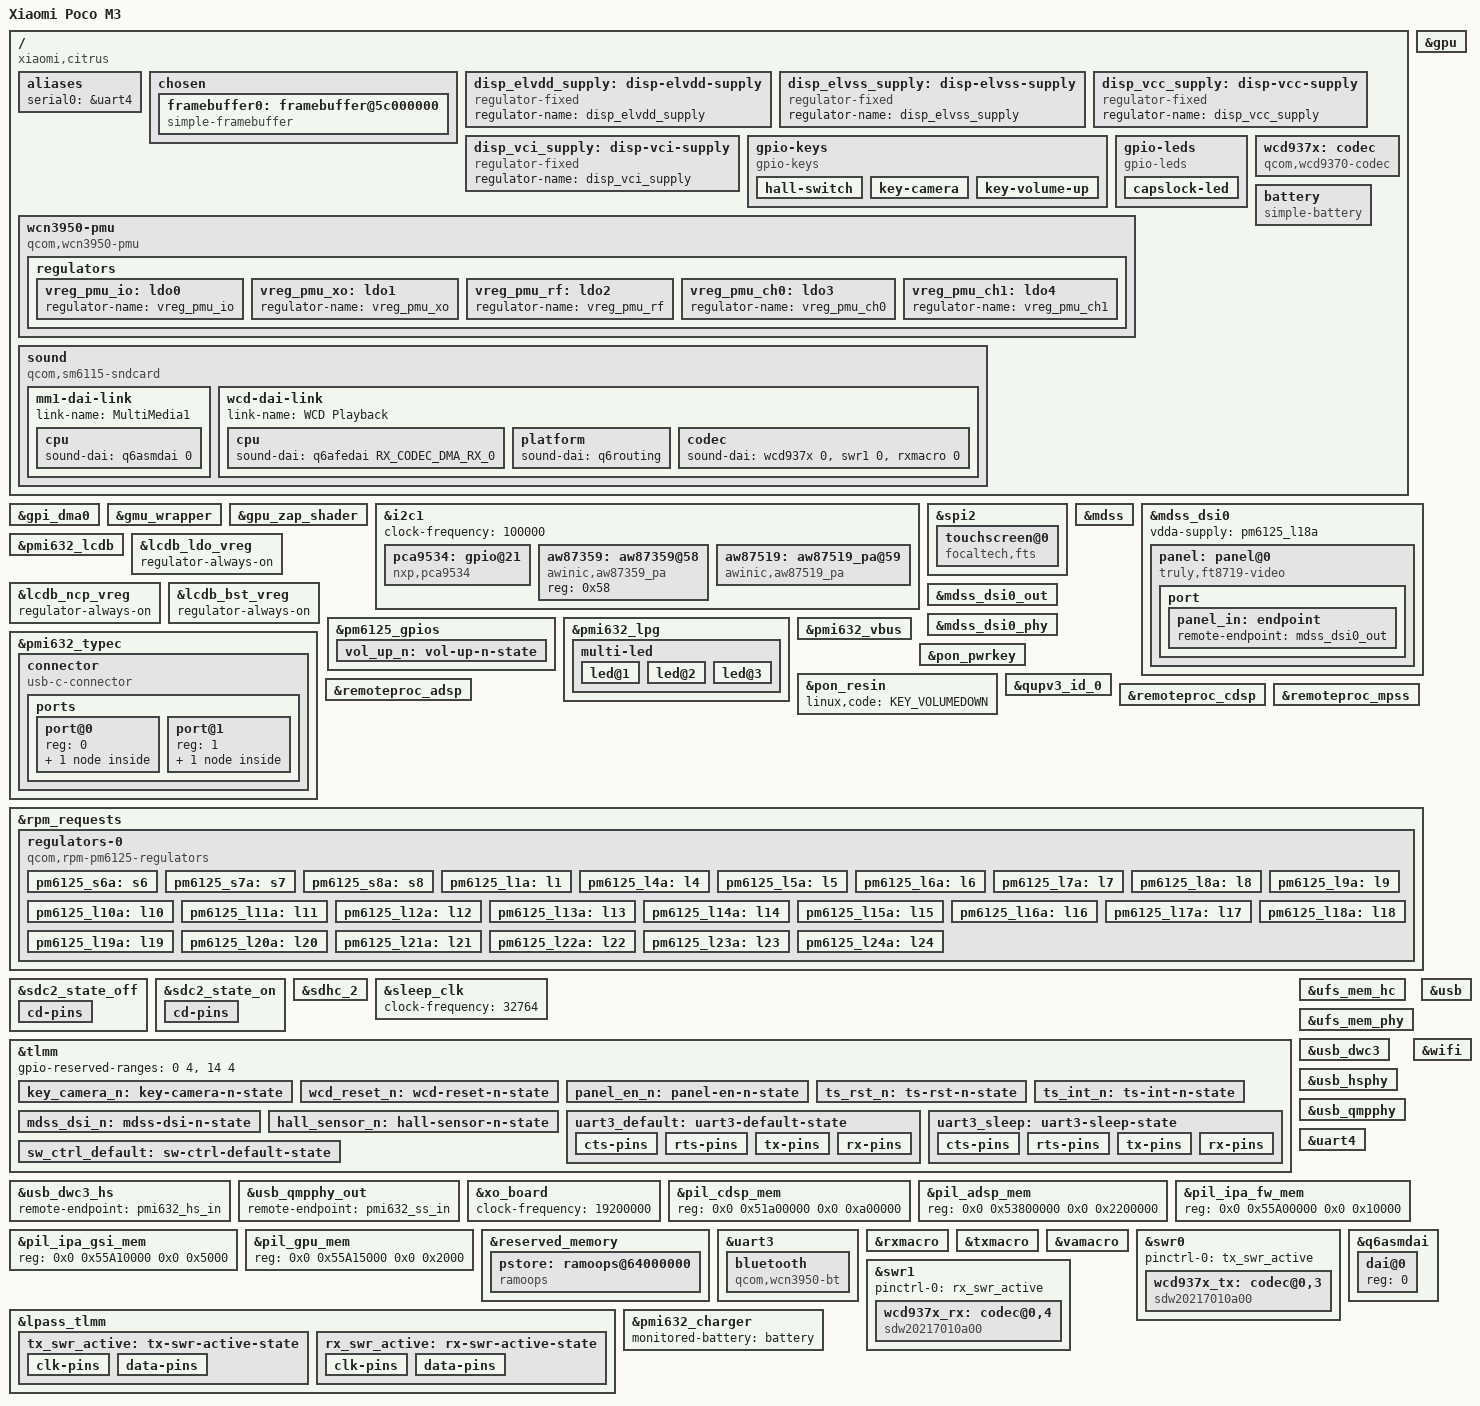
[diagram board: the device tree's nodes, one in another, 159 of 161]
// SPDX-License-Identifier: (GPL-2.0+ OR BSD-3-Clause)
/*
 * Copyright (c) 2023 - 2024, Dang Huynh <danct12@riseup.net>
 */

/dts-v1/;

#include "sm6115.dtsi"
#include "pm6125.dtsi"
#include "pmi632.dtsi"
#include <dt-bindings/arm/qcom,ids.h>
#include <dt-bindings/leds/common.h>
#include <dt-bindings/usb/pd.h>
#include <dt-bindings/interconnect/qcom,sm6115.h>

/ {
	model = "Xiaomi Poco M3";
	compatible = "xiaomi,citrus", "qcom,sm6115";
	chassis-type = "handset";

	qcom,msm-id = <0x1a1 0x10000 0x1bc 0x10000>;
	qcom,board-id = <0x00 0x303>;

	aliases {
		serial0 = &uart4;
	};

	chosen {
		#address-cells = <2>;
		#size-cells = <2>;
		ranges;

		framebuffer0: framebuffer@5c000000 {
			compatible = "simple-framebuffer";
			reg = <0x0 0x5c000000 0x0 (1080 * 2160 * 4)>;
			width = <1080>;
			height = <2160>;
			stride = <(1080 * 4)>;
			format = "a8r8g8b8";
			clocks = <&gcc GCC_DISP_HF_AXI_CLK>;
		};
	};

	disp_elvdd_supply: disp-elvdd-supply {
		compatible = "regulator-fixed";
		regulator-name = "disp_elvdd_supply";
	};

	disp_elvss_supply: disp-elvss-supply {
		compatible = "regulator-fixed";
		regulator-name = "disp_elvss_supply";
	};

	disp_vcc_supply: disp-vcc-supply {
		compatible = "regulator-fixed";
		regulator-name = "disp_vcc_supply";
	};

	disp_vci_supply: disp-vci-supply {
		compatible = "regulator-fixed";
		regulator-name = "disp_vci_supply";
	};

	gpio-keys {
		compatible = "gpio-keys";

		pinctrl-0 = <&hall_sensor_n>, <&key_camera_n>, <&vol_up_n>;
		pinctrl-names = "default";

		hall-switch {
			label = "Hall Switch";
			linux,input-type = <EV_SW>;
			linux,code = <SW_LID>;
			gpios = <&tlmm 96 GPIO_ACTIVE_HIGH>;
			debounce-interval = <90>;
			wakeup-source;
		};

		key-camera {
			label = "Camera Button";
			linux,code = <KEY_CAMERA>;
			gpios = <&tlmm 18 GPIO_ACTIVE_LOW>;
			debounce-interval = <15>;
		};

		key-volume-up {
			label = "Volume Up";
			linux,code = <KEY_VOLUMEUP>;
			gpios = <&pm6125_gpios 5 GPIO_ACTIVE_LOW>;
			debounce-interval = <15>;
			linux,can-disable;
			wakeup-source;
		};
	};

	gpio-leds {
		compatible = "gpio-leds";

		capslock-led {
			label = "green:capslock";
			function = LED_FUNCTION_CAPSLOCK;
			color = <LED_COLOR_ID_GREEN>;
			gpios = <&pca9534 1 GPIO_ACTIVE_HIGH>;
			linux,default-trigger = "kbd-capslock";
			default-state = "off";
		};
	};

};

&gpi_dma0 {
	status = "okay";
};

&gpu {
	status = "okay";
};

&gmu_wrapper {
	interconnects = <&bimc MASTER_GRAPHICS_3D 0 &bimc SLAVE_EBI_CH0 0>;
	interconnect-names = "gfx-mem";
};

&gpu_zap_shader {
	firmware-name = "qcom/sm6115/xiaomi-citrus/a610_zap.mbn";
};

&i2c1 {
	clock-frequency = <100000>;

	status = "okay";

	pca9534: gpio@21 {
		compatible = "nxp,pca9534";
		reg = <0x21>;
		gpio-controller;
		#gpio-cells = <2>;
	};

	aw87359: aw87359@58 {
		compatible = "awinic,aw87359_pa";
		reg = <0x58>;
	};

	aw87519: aw87519_pa@59 {
		compatible = "awinic,aw87519_pa";
		reg = <0x59>;
		reset-gpios = <&tlmm 98 GPIO_ACTIVE_HIGH>;
	};
};

&spi2 {
	status = "okay";


	touchscreen@0 {
		compatible = "focaltech,fts";
		reg = <0>;
		spi-max-frequency = <6000000>;

		focaltech,reset-gpios = <&tlmm 103 GPIO_ACTIVE_LOW>;
		focaltech,irq-gpios = <&tlmm 93 GPIO_ACTIVE_HIGH>;

		focaltech,max-touch-number = <10>;
		focaltech,display-coords = <0 0 1080 2340>;
	};
};

&mdss {
	status = "okay";
};

&mdss_dsi0 {
	vdda-supply = <&pm6125_l18a>;
	status = "okay";

	panel: panel@0 {
		compatible = "truly,ft8719-video";
		reg = <0>;

		reset-gpios = <&tlmm 82 GPIO_ACTIVE_LOW>;

		vddio-supply = <&pm6125_l9a>;

		pinctrl-0 = <&mdss_dsi_n &panel_en_n>;
		pinctrl-names = "default";

		port {
			panel_in: endpoint {
				remote-endpoint = <&mdss_dsi0_out>;
			};
		};
	};
};

&pmi632_lcdb {
	status = "okay";
};

&lcdb_ldo_vreg {
	regulator-always-on;
};

&lcdb_ncp_vreg {
	regulator-always-on;
};

&lcdb_bst_vreg {
	regulator-always-on;
};

&mdss_dsi0_out {
	data-lanes = <0 1 2 3>;
	remote-endpoint = <&panel_in>;
};

&mdss_dsi0_phy {
	status = "okay";
};

&pm6125_gpios {
	vol_up_n: vol-up-n-state {
		pins = "gpio5";
		function = "normal";
		power-source = <0>;
		bias-pull-up;
		input-enable;
	};
};

&pmi632_lpg {
	status = "okay";

	multi-led {
		color = <LED_COLOR_ID_RGB>;
		function = LED_FUNCTION_STATUS;

		#address-cells = <1>;
		#size-cells = <0>;

		led@1 {
			reg = <1>;
			color = <LED_COLOR_ID_RED>;
		};

		led@2 {
			reg = <2>;
			color = <LED_COLOR_ID_GREEN>;
		};

		led@3 {
			reg = <3>;
			color = <LED_COLOR_ID_BLUE>;
		};
	};
};

&pmi632_typec {
	status = "okay";

	connector {
		compatible = "usb-c-connector";

		power-role = "dual";
		data-role = "dual";
		self-powered;

		typec-power-opmode = "default";
		pd-disable;

		vbus-supply = <&pmi632_vbus>;

		ports {
			#address-cells = <1>;
			#size-cells = <0>;

			port@0 {
				reg = <0>;
				pmi632_hs_in: endpoint {
					remote-endpoint = <&usb_dwc3_hs>;
				};
			};

			port@1 {
				reg = <1>;
				pmi632_ss_in: endpoint {
					remote-endpoint = <&usb_qmpphy_out>;
				};
			};
		};
	};
};

&pmi632_vbus {
	regulator-min-microamp = <500000>;
	regulator-max-microamp = <1000000>;
	status = "okay";
};

&pon_pwrkey {
	status = "okay";
};

&pon_resin {
	linux,code = <KEY_VOLUMEDOWN>;
	status = "okay";
};

&qupv3_id_0 {
	status = "okay";
};

&remoteproc_adsp {
	firmware-name = "qcom/sm6115/xiaomi-citrus/adsp.mdt";
	status = "okay";
};

&remoteproc_cdsp {
	firmware-name = "qcom/sm6115/xiaomi-citrus/cdsp.mdt";
	status = "okay";
};

&remoteproc_mpss {
	firmware-name = "qcom/sm6115/xiaomi-citrus/modem.mdt";
	status = "okay";
};

&rpm_requests {
	regulators-0 {
		compatible = "qcom,rpm-pm6125-regulators";

		pm6125_s6a: s6 {
			regulator-min-microvolt = <304000>;
			regulator-max-microvolt = <1456000>;
		};

		pm6125_s7a: s7 {
			regulator-min-microvolt = <1280000>;
			regulator-max-microvolt = <2040000>;
		};

		pm6125_s8a: s8 {
			regulator-min-microvolt = <1064000>;
			regulator-max-microvolt = <1304000>;
		};

		pm6125_l1a: l1 {
			regulator-min-microvolt = <952000>;
			regulator-max-microvolt = <1152000>;
		};

		pm6125_l4a: l4 {
			regulator-min-microvolt = <488000>;
			regulator-max-microvolt = <1000000>;
		};

		pm6125_l5a: l5 {
			regulator-min-microvolt = <1648000>;
			regulator-max-microvolt = <3056000>;
			regulator-allow-set-load;
		};

		pm6125_l6a: l6 {
			regulator-min-microvolt = <576000>;
			regulator-max-microvolt = <656000>;
		};

		pm6125_l7a: l7 {
			regulator-min-microvolt = <1200000>;
			regulator-max-microvolt = <1304000>;
		};

		pm6125_l8a: l8 {
			regulator-min-microvolt = <400000>;
			regulator-max-microvolt = <728000>;
		};

		pm6125_l9a: l9 {
			regulator-min-microvolt = <1800000>;
			regulator-max-microvolt = <2000000>;
		};

		pm6125_l10a: l10 {
			regulator-min-microvolt = <1704000>;
			regulator-max-microvolt = <1904000>;
		};

		pm6125_l11a: l11 {
			regulator-min-microvolt = <1704000>;
			regulator-max-microvolt = <1952000>;
			regulator-allow-set-load;
		};

		pm6125_l12a: l12 {
			regulator-min-microvolt = <1624000>;
			regulator-max-microvolt = <1984000>;
		};

		pm6125_l13a: l13 {
			regulator-min-microvolt = <1504000>;
			regulator-max-microvolt = <1952000>;
		};

		pm6125_l14a: l14 {
			regulator-min-microvolt = <1704000>;
			regulator-max-microvolt = <1904000>;
		};

		pm6125_l15a: l15 {
			regulator-min-microvolt = <2920000>;
			regulator-max-microvolt = <3232000>;
		};

		pm6125_l16a: l16 {
			regulator-min-microvolt = <1704000>;
			regulator-max-microvolt = <1904000>;
		};

		pm6125_l17a: l17 {
			regulator-min-microvolt = <1152000>;
			regulator-max-microvolt = <1384000>;
		};

		pm6125_l18a: l18 {
			regulator-min-microvolt = <1104000>;
			regulator-max-microvolt = <1312000>;
		};

		pm6125_l19a: l19 {
			regulator-min-microvolt = <1624000>;
			regulator-max-microvolt = <3304000>;
		};

		pm6125_l20a: l20 {
			regulator-min-microvolt = <1624000>;
			regulator-max-microvolt = <3304000>;
		};

		pm6125_l21a: l21 {
			regulator-min-microvolt = <2400000>;
			regulator-max-microvolt = <3600000>;
		};

		pm6125_l22a: l22 {
			regulator-min-microvolt = <2952000>;
			regulator-max-microvolt = <3304000>;
		};

		pm6125_l23a: l23 {
			regulator-min-microvolt = <3200000>;
			regulator-max-microvolt = <3400000>;
		};

		pm6125_l24a: l24 {
			regulator-min-microvolt = <2704000>;
			regulator-max-microvolt = <3600000>;
			regulator-allow-set-load;
		};
	};
};

&sdc2_state_off {
	cd-pins {
		pins = "gpio88";
		function = "gpio";
		drive-strength = <2>;
		bias-disable;
	};
};

&sdc2_state_on {
	cd-pins {
		pins = "gpio88";
		function = "gpio";
		drive-strength = <2>;
		bias-pull-up;
	};
};

&sdhc_2 {
	pinctrl-0 = <&sdc2_state_on>;
	pinctrl-1 = <&sdc2_state_off>;
	pinctrl-names = "default", "sleep";

	cd-gpios = <&tlmm 88 GPIO_ACTIVE_HIGH>;

	vmmc-supply = <&pm6125_l22a>;
	vqmmc-supply = <&pm6125_l5a>;

	status = "okay";
};

&sleep_clk {
	clock-frequency = <32764>;
};

&tlmm {
	gpio-reserved-ranges = <0 4>, <14 4>;

	key_camera_n: key-camera-n-state {
		pins = "gpio18";
		function = "gpio";
		drive-strength = <2>;
		bias-pull-up;
	};

	wcd_reset_n: wcd-reset-n-state {
		pins = "gpio92";
		function = "gpio";
		drive-strength = <16>;
		output-high;
	};

	panel_en_n: panel-en-n-state {
		pins = "gpio65";
		function = "gpio";
		bias-disable;
	};

	ts_rst_n: ts-rst-n-state {
		pins = "gpio103";
		function = "gpio";
		drive-strength = <8>;
		bias-pull-up;
	};

	ts_int_n: ts-int-n-state {
		pins = "gpio93";
		function = "gpio";
		drive-strength = <8>;
		bias-pull-up;
	};

	mdss_dsi_n: mdss-dsi-n-state {
		pins = "gpio82";
		function = "gpio";
		drive-strength = <8>;
		bias-disable;
	};

	hall_sensor_n: hall-sensor-n-state {
		pins = "gpio96";
		function = "gpio";
		drive-strength = <2>;
		bias-pull-up;
	};

	uart3_default: uart3-default-state {
		cts-pins {
			pins = "gpio8";
			function = "qup3";
			drive-strength = <2>;
			bias-bus-hold;
		};

		rts-pins {
			pins = "gpio9";
			function = "qup3";
			drive-strength = <2>;
			bias-disable;
		};

		tx-pins {
			pins = "gpio10";
			function = "qup3";
			drive-strength = <2>;
			bias-disable;
		};

		rx-pins {
			pins = "gpio11";
			function = "qup3";
			drive-strength = <2>;
			bias-pull-up;
		};
	};

	uart3_sleep: uart3-sleep-state {
		cts-pins {
			pins = "gpio8";
			function = "gpio";
			drive-strength = <2>;
			bias-bus-hold;
		};

		rts-pins {
			pins = "gpio9";
			function = "gpio";
			drive-strength = <2>;
			bias-pull-down;
		};

		tx-pins {
			pins = "gpio10";
			function = "gpio";
			drive-strength = <2>;
			bias-pull-up;
		};

		rx-pins {
			pins = "gpio11";
			function = "gpio";
			drive-strength = <2>;
			bias-pull-up;
		};
	};

	sw_ctrl_default: sw-ctrl-default-state {
		pins = "gpio87";
		function = "gpio";
		bias-pull-down;
	};
};

&ufs_mem_hc {
	vcc-supply = <&pm6125_l24a>;
	vcc-max-microamp = <600000>;
	vccq2-supply = <&pm6125_l11a>;
	vccq2-max-microamp = <600000>;
	vdd-hba-supply = <&pm6125_l18a>;
	status = "okay";
};

&ufs_mem_phy {
	vdda-phy-supply = <&pm6125_l4a>;
	vdda-pll-supply = <&pm6125_l12a>;

	status = "okay";
};

&usb {
	status = "okay";
};

&usb_dwc3 {
	status = "okay";
};

&usb_hsphy {
	vdd-supply = <&pm6125_l4a>;
	vdda-pll-supply = <&pm6125_l12a>;
	vdda-phy-dpdm-supply = <&pm6125_l15a>;
	status = "okay";
};

&usb_qmpphy {
	/delete-property/ orientation-switch;

	vdda-phy-supply = <&pm6125_l4a>;
	vdda-pll-supply = <&pm6125_l12a>;
	status = "okay";
};

&usb_dwc3_hs {
	remote-endpoint = <&pmi632_hs_in>;
};

&usb_qmpphy_out {
	remote-endpoint = <&pmi632_ss_in>;
};

&wifi {
	vdd-0.8-cx-mx-supply = <&pm6125_l4a>;
	vdd-1.8-xo-supply = <&pm6125_l16a>;
	vdd-1.3-rfa-supply = <&pm6125_l17a>;
	vdd-3.3-ch0-supply = <&pm6125_l23a>;
	vdd-3.3-ch1-supply = <&pm6125_l24a>;

	status = "okay";
};

&xo_board {
	clock-frequency = <19200000>;
};

&uart4 {
        status = "okay";
};

/* Restore memory regions to match stock/downstream firmware expectations
 * (TrustZone/hypervisor on this device only recognizes these addresses)
 */
&pil_cdsp_mem {
	reg = <0x0 0x51a00000 0x0 0xa00000>;
};

&pil_adsp_mem {
	reg = <0x0 0x53800000 0x0 0x2200000>;
};

&pil_ipa_fw_mem {
	reg = <0x0 0x55A00000 0x0 0x10000>;
};

&pil_ipa_gsi_mem {
	reg = <0x0 0x55A10000 0x0 0x5000>;
};

&pil_gpu_mem {
	reg = <0x0 0x55A15000 0x0 0x2000>;
};

/delete-node/ &cdsp_sec_mem;

&reserved_memory {
	pstore: ramoops@64000000 {
		compatible = "ramoops";
		reg = <0x0 0x64000000 0x0 0x400000>;
		record-size = <0x100000>;
		console-size = <0x100000>;
		pmsg-size = <0x200000>;
		ftrace-size = <0x0>;
	};
};

/ {
	wcn3950-pmu {
		compatible = "qcom,wcn3950-pmu";

		pinctrl-0 = <&sw_ctrl_default>;
		pinctrl-names = "default";

		vddio-supply = <&pm6125_l9a>;
		vddxo-supply = <&pm6125_l16a>;
		vddrf-supply = <&pm6125_l17a>;
		vddch0-supply = <&pm6125_l23a>;

		swctrl-gpios = <&tlmm 87 GPIO_ACTIVE_HIGH>;

		regulators {
			vreg_pmu_io: ldo0 { regulator-name = "vreg_pmu_io"; };
			vreg_pmu_xo: ldo1 { regulator-name = "vreg_pmu_xo"; };
			vreg_pmu_rf: ldo2 { regulator-name = "vreg_pmu_rf"; };
			vreg_pmu_ch0: ldo3 { regulator-name = "vreg_pmu_ch0"; };
			vreg_pmu_ch1: ldo4 { regulator-name = "vreg_pmu_ch1"; };
		};
	};
};

&uart3 {
	pinctrl-0 = <&uart3_default>;
	pinctrl-1 = <&uart3_sleep>;
	pinctrl-names = "default", "sleep";

	status = "okay";

	bluetooth {
		compatible = "qcom,wcn3950-bt";
		vddio-supply = <&vreg_pmu_io>;
		vddxo-supply = <&vreg_pmu_xo>;
		vddrf-supply = <&vreg_pmu_rf>;
		vddch0-supply = <&vreg_pmu_ch0>;
	};
};


&rxmacro {
	status = "okay";
};

&txmacro {
	status = "okay";
};

&vamacro {
	status = "okay";
};

&swr0 {
	status = "okay";
	pinctrl-names = "default";
	pinctrl-0 = <&tx_swr_active>;

	wcd937x_tx: codec@0,3 {
		compatible = "sdw20217010a00";
		reg = <0 3>;
		qcom,tx-port-mapping = <1 1 2 3>;
	};
};

&swr1 {
	status = "okay";
	pinctrl-names = "default";
	pinctrl-0 = <&rx_swr_active>;

	wcd937x_rx: codec@0,4 {
		compatible = "sdw20217010a00";
		reg = <0 4>;
		qcom,rx-port-mapping = <1 2 3 4 5>;
	};
};

/ {
	wcd937x: codec {
		compatible = "qcom,wcd9370-codec";
		pinctrl-0 = <&wcd_reset_n>;
		pinctrl-names = "default";
		reset-gpios = <&tlmm 92 GPIO_ACTIVE_LOW>;
		vdd-buck-supply = <&pm6125_l14a>;
		vdd-rxtx-supply = <&pm6125_l9a>;
		vdd-px-supply = <&pm6125_l9a>;
		qcom,micbias1-microvolt = <1800000>;
		qcom,micbias2-microvolt = <1800000>;
		qcom,micbias3-microvolt = <1800000>;
		qcom,micbias4-microvolt = <1800000>;
		qcom,rx-device = <&wcd937x_rx>;
		qcom,tx-device = <&wcd937x_tx>;
		#sound-dai-cells = <1>;
	};
};

/ {
	sound: sound {
		compatible = "qcom,sm6115-sndcard";
		model = "Xiaomi-Poco-M3-Citrus";

		top-speaker-amp = <&aw87359>;
		bottom-speaker-amp = <&aw87519>;
		audio-routing = "IN3_AUX", "AUX_OUT",
				"Top Spk Amp", "EAR",
				"Bottom Spk Amp", "AUX";

		mm1-dai-link {
			link-name = "MultiMedia1";
			cpu {
				sound-dai = <&q6asmdai 0>;
			};
		};

		wcd-dai-link {
			link-name = "WCD Playback";

			cpu {
				sound-dai = <&q6afedai RX_CODEC_DMA_RX_0>;
			};

			platform {
				sound-dai = <&q6routing>;
			};

			codec {
				sound-dai = <&wcd937x 0>, <&swr1 0>, <&rxmacro 0>;
			};
		};
	};
};

&q6asmdai {
	dai@0 {
		reg = <0>;
	};
};

&lpass_tlmm {
	tx_swr_active: tx-swr-active-state {
		clk-pins {
			pins = "gpio0";
			function = "swr_tx_clk";
			drive-strength = <10>;
			bias-disable;
		};
		data-pins {
			pins = "gpio1", "gpio2";
			function = "swr_tx_data";
			drive-strength = <10>;
			bias-bus-hold;
		};
	};

	rx_swr_active: rx-swr-active-state {
		clk-pins {
			pins = "gpio3";
			function = "swr_rx_clk";
			drive-strength = <10>;
			bias-disable;
		};
		data-pins {
			pins = "gpio4", "gpio5";
			function = "swr_rx_data";
			drive-strength = <10>;
			bias-bus-hold;
		};
	};
};


/ {
	battery: battery {
		compatible = "simple-battery";
		voltage-min-design-microvolt = <3400000>;
		voltage-max-design-microvolt = <4450000>;
		constant-charge-voltage-max-microvolt = <4450000>;
		constant-charge-current-max-microamp = <2000000>;
		charge-full-design-microamp-hours = <6000000>;
		charge-term-current-microamp = <350000>;
	};
};

&pmi632_charger {
	monitored-battery = <&battery>;
	status = "okay";
};
